# PIC32MZ1024EFF144 register map
Vendor: Microchip
Registers are 32-bit, read-write, reset 0x0 unless marked. A register's access mark holds for its fields unless they carry their own. Addresses are absolute, and some are shared; only a register's first bit layout is shown; [hi:lo] are bit positions.

## UART1
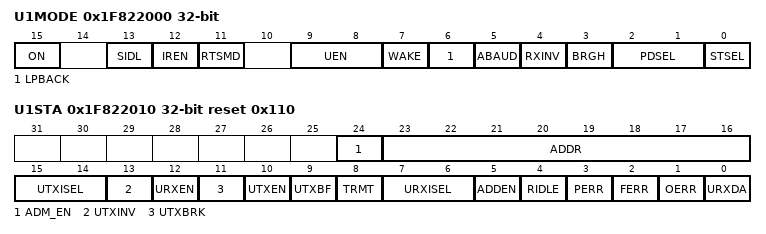
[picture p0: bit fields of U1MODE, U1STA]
0x1F822000 U1MODE
  [15] ON, [13] SIDL, [12] IREN, [11] RTSMD, [9:8] UEN, [7] WAKE, [6] LPBACK, [5] ABAUD, [4] RXINV, [3] BRGH, [2:1] PDSEL, [0] STSEL
0x1F822010 U1STA reset 0x110
  [24] ADM_EN
  [23:16] ADDR
  [15:14] UTXISEL
  [13] UTXINV
  [12] URXEN
  [11] UTXBRK
  [10] UTXEN
  [9] UTXBF ro
  [8] TRMT ro
  [7:6] URXISEL
  [5] ADDEN
  [4] RIDLE ro
  [3] PERR ro
  [2] FERR ro
  [1] OERR — (can only be cleared)
  [0] URXDA ro
0x1F822020 U1TXREG reset not defined — (power-on value -----------------------xxxxxxxxx)
  [8:0] U1TXREG
0x1F822030 U1RXREG ro
  [8:0] U1RXREG
0x1F822040 U1BRG
  [15:0] BRG

## UART2
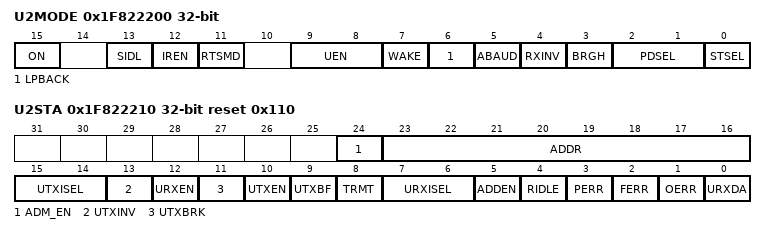
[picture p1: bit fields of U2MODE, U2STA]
0x1F822200 U2MODE
  [15] ON, [13] SIDL, [12] IREN, [11] RTSMD, [9:8] UEN, [7] WAKE, [6] LPBACK, [5] ABAUD, [4] RXINV, [3] BRGH, [2:1] PDSEL, [0] STSEL
0x1F822210 U2STA reset 0x110
  [24] ADM_EN
  [23:16] ADDR
  [15:14] UTXISEL
  [13] UTXINV
  [12] URXEN
  [11] UTXBRK
  [10] UTXEN
  [9] UTXBF ro
  [8] TRMT ro
  [7:6] URXISEL
  [5] ADDEN
  [4] RIDLE ro
  [3] PERR ro
  [2] FERR ro
  [1] OERR — (can only be cleared)
  [0] URXDA ro
0x1F822220 U2TXREG reset not defined — (power-on value -----------------------xxxxxxxxx)
  [8:0] U2TXREG
0x1F822230 U2RXREG ro
  [8:0] U2RXREG
0x1F822240 U2BRG
  [15:0] BRG

## UART3
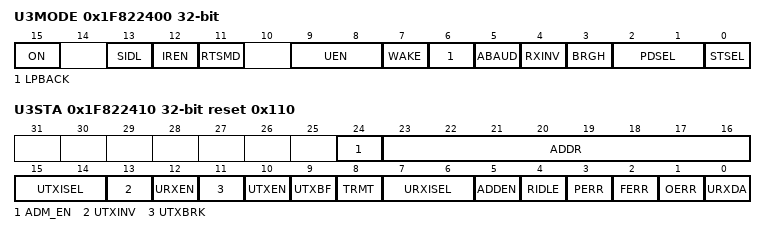
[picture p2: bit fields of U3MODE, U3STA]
0x1F822400 U3MODE
  [15] ON, [13] SIDL, [12] IREN, [11] RTSMD, [9:8] UEN, [7] WAKE, [6] LPBACK, [5] ABAUD, [4] RXINV, [3] BRGH, [2:1] PDSEL, [0] STSEL
0x1F822410 U3STA reset 0x110
  [24] ADM_EN
  [23:16] ADDR
  [15:14] UTXISEL
  [13] UTXINV
  [12] URXEN
  [11] UTXBRK
  [10] UTXEN
  [9] UTXBF ro
  [8] TRMT ro
  [7:6] URXISEL
  [5] ADDEN
  [4] RIDLE ro
  [3] PERR ro
  [2] FERR ro
  [1] OERR — (can only be cleared)
  [0] URXDA ro
0x1F822420 U3TXREG reset not defined — (power-on value -----------------------xxxxxxxxx)
  [8:0] U3TXREG
0x1F822430 U3RXREG ro
  [8:0] U3RXREG
0x1F822440 U3BRG
  [15:0] BRG

## UART4
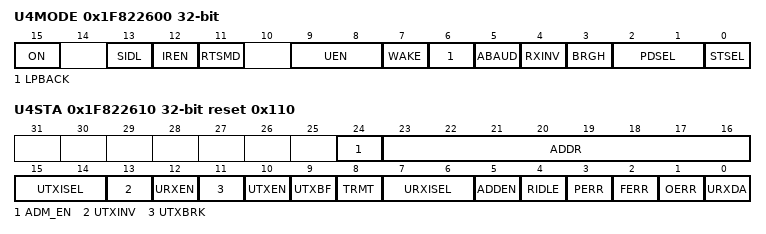
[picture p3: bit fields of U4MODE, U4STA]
0x1F822600 U4MODE
  [15] ON, [13] SIDL, [12] IREN, [11] RTSMD, [9:8] UEN, [7] WAKE, [6] LPBACK, [5] ABAUD, [4] RXINV, [3] BRGH, [2:1] PDSEL, [0] STSEL
0x1F822610 U4STA reset 0x110
  [24] ADM_EN
  [23:16] ADDR
  [15:14] UTXISEL
  [13] UTXINV
  [12] URXEN
  [11] UTXBRK
  [10] UTXEN
  [9] UTXBF ro
  [8] TRMT ro
  [7:6] URXISEL
  [5] ADDEN
  [4] RIDLE ro
  [3] PERR ro
  [2] FERR ro
  [1] OERR — (can only be cleared)
  [0] URXDA ro
0x1F822620 U4TXREG reset not defined — (power-on value -----------------------xxxxxxxxx)
  [8:0] U4TXREG
0x1F822630 U4RXREG ro
  [8:0] U4RXREG
0x1F822640 U4BRG
  [15:0] BRG

## UART5
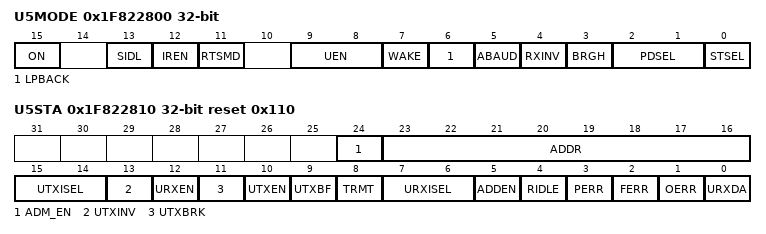
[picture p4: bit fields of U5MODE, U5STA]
0x1F822800 U5MODE
  [15] ON, [13] SIDL, [12] IREN, [11] RTSMD, [9:8] UEN, [7] WAKE, [6] LPBACK, [5] ABAUD, [4] RXINV, [3] BRGH, [2:1] PDSEL, [0] STSEL
0x1F822810 U5STA reset 0x110
  [24] ADM_EN
  [23:16] ADDR
  [15:14] UTXISEL
  [13] UTXINV
  [12] URXEN
  [11] UTXBRK
  [10] UTXEN
  [9] UTXBF ro
  [8] TRMT ro
  [7:6] URXISEL
  [5] ADDEN
  [4] RIDLE ro
  [3] PERR ro
  [2] FERR ro
  [1] OERR — (can only be cleared)
  [0] URXDA ro
0x1F822820 U5TXREG reset not defined — (power-on value -----------------------xxxxxxxxx)
  [8:0] U5TXREG
0x1F822830 U5RXREG ro
  [8:0] U5RXREG
0x1F822840 U5BRG
  [15:0] BRG

## UART6
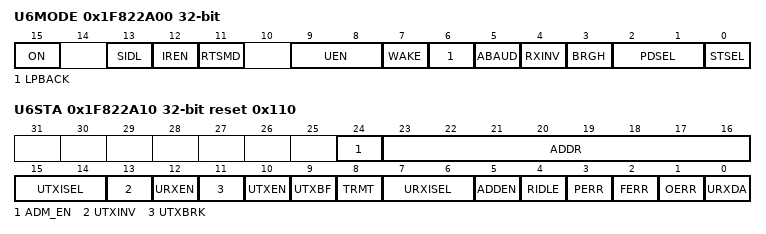
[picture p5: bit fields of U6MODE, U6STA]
0x1F822A00 U6MODE
  [15] ON, [13] SIDL, [12] IREN, [11] RTSMD, [9:8] UEN, [7] WAKE, [6] LPBACK, [5] ABAUD, [4] RXINV, [3] BRGH, [2:1] PDSEL, [0] STSEL
0x1F822A10 U6STA reset 0x110
  [24] ADM_EN
  [23:16] ADDR
  [15:14] UTXISEL
  [13] UTXINV
  [12] URXEN
  [11] UTXBRK
  [10] UTXEN
  [9] UTXBF ro
  [8] TRMT ro
  [7:6] URXISEL
  [5] ADDEN
  [4] RIDLE ro
  [3] PERR ro
  [2] FERR ro
  [1] OERR — (can only be cleared)
  [0] URXDA ro
0x1F822A20 U6TXREG reset not defined — (power-on value -----------------------xxxxxxxxx)
  [8:0] U6TXREG
0x1F822A30 U6RXREG ro
  [8:0] U6RXREG
0x1F822A40 U6BRG
  [15:0] BRG
